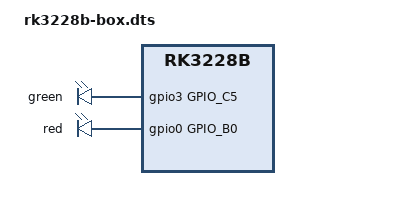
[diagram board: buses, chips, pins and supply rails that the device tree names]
/dts-v1/;

#include "rk3228b.dtsi"
#include "lcd-box.dtsi"
#include <dt-bindings/input/input.h>
#include "rk322x-sdk.dtsi"

/ {
	wireless-wlan {
		wifi_chip_type = "rtl8189es";
	};

	wireless-bluetooth {
		status = "disabled";
	};

	power-led {
		compatible = "gpio-leds";
		green {
			gpios = <&gpio3 GPIO_C5 GPIO_ACTIVE_HIGH>;
			default-state = "on";
		};
		red {
			gpios = <&gpio0 GPIO_B0 GPIO_ACTIVE_HIGH>;
			default-state = "off";
		};
	};
};

